# K1921VG1T register map
Vendor: NIIET; Series: K1921VGx; File version: 2.8
CPU: other r0p1, little endian, MPU, FPU, 4 interrupt priority bits
Registers are 32-bit, read-write, reset 0x0 unless marked. A register's access mark holds for its fields unless they carry their own. Offsets are from the block's base; [hi:lo] are bit positions; {n}, {i} and the like mark numbered series; 'fields as' and 'values as' point back to an identical list.

## DAC0 — DAC control registers
Base 0x51004000
Same registers: DAC1 0x51005000
0x00 DATA12 — Output data register (12-bit)
  [11:0] VAL
0x04 DATA8 — Output data register (8-bit)
  [7:0] VAL — Write 8 most significant bits (4 less significant bits will be set to 0)
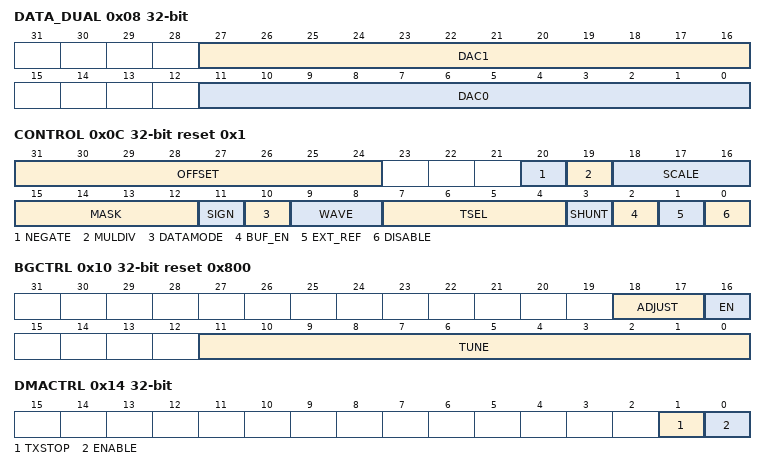
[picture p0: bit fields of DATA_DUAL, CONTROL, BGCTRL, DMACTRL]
0x08 DATA_DUAL — Output data register (Dual mode and DAC0 only)
  [27:16] DAC1 — Value for DAC1 in Dual mode
  [11:0] DAC0 — Value for DAC0 in Dual mode
0x0C CONTROL reset 0x1
  [31:24] OFFSET — Offset for pattern generator
  [20] NEGATE — Convert data to it's two's complement value
  [19] MULDIV — Switch between up and downscale
    0=DOWNSCALE (division (shift SCALE positions to the right)); 1=UPSCALE (multiplication (shift SCALE positions to the left))
  [18:16] SCALE — Scale value for up/downscale input data in steps by power of 2
    0=NOSHIFT (multiplication/division by 1); 1=SHIFT1 (multiplication/division by 2); 2=SHIFT2 (multiplication/division by 4); 3=SHIFT3 (multiplication/division by 8); 4=SHIFT4 (multiplication/division by 16); 5=SHIFT5 (multiplication/division by 32); 6=SHIFT6 (multiplication/division by 64); 7=SHIFT7 (multiplication/division by 128)
  [15:12] MASK — DAC channel mask/amplitude selector
  [11] SIGN — Signed DAC mode enable
    0=UNSIGNED (Data treated as unsigned value); 1=SIGNED (Data treated as signed values)
  [10] DATAMODE — Switch between independent and simultaneous DAC mode
    0=INDEPENDENT (Independent DAC mode); 1=SIMULTANEOUS (Simultaneous DAC mode)
  [9:8] WAVE — DAC channel wave generation enable
    0=NONE (Wave generation disabled); 1=NOISE (Noise wave generation enable); 2=TRIANGULAR (Triangular wave generation enable); 3=PATTERN (Pattern generator enable)
  [7:4] TSEL — Select DAC trigger event
    0=SWTRIG (software request by SWTRIG bit); 1=HWTRIG (hardware request from internal trigger generator); 2=TMR0123 (Timer 0 or Timer 1 or Timer 2 or Timer 3 request); 3=TMR4567 (Timer 4 or Timer 5 or Timer 6 or Timer 7 request); 4=TMR89AB (Timer 8 or Timer 9 or Timer 10 or Timer 11 request); 5=TMRCDEF (Timer 12 or Timer 13 or Timer 14 or Timer 15 request); 6=GPIOAB (GPIO A or GPIO B interrupt); 7=GPIOCD (GPIO C or GPIO D interrupt); 8=GPIOEF (GPIO E or GPIO F interrupt); 9=GPIOG (GPIO G interrupt); 10=PWMAGRP (Combined all 16 A channels of PWMs); 11=PWMBGRP (Combined all 16 B channels of PWMs)
  [3] SHUNT — Enable shunt resistor (test use only)
  [2] BUF_EN — Enable output buffer
  [1] EXT_REF — Use external reference voltage source
    0=INTERNAL_REF (Use internal reference volatage source); 1=EXTERNAL_REF (Use external 3.3 V reference volatage source)
  [0] DISABLE — Disable DAC block
0x10 BGCTRL reset 0x800 — Internal reference-voltage source (adjustable BandGap) register
  [18:17] ADJUST — Adjust output voltage of internal reference-voltage source
    0=V_1p5 (Output 1.5 V); 1=V_1p8 (Output 1.8 V); 2=V_2p048 (Output 2.048 V); 3=V_2p5 (Output 2.5 V)
  [16] EN — Turn-on internal reference-voltage source
  [11:0] TUNE — Tune bandgap voltage
0x14 DMACTRL — DAC DMA control register
  [1] TXSTOP — Automatic clear DMA TX request generation when channel ends all transactions
  [0] ENABLE — DMA request generation enable
0x18 SWTRIG wo — Software trigger control register
  [0] SWTRIG — Software trigger
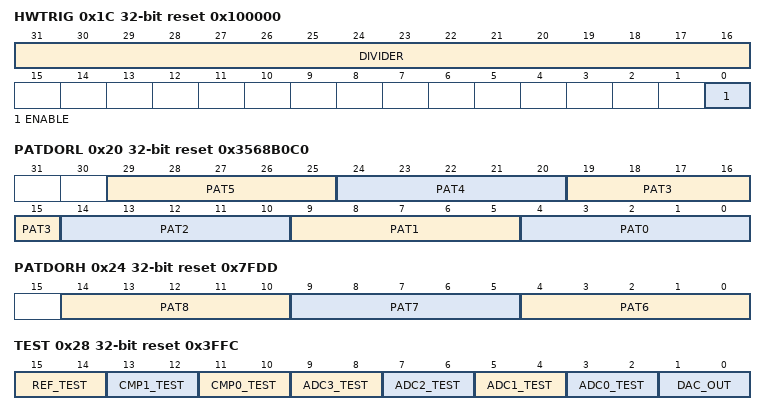
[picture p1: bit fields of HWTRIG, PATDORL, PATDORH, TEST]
0x1C HWTRIG reset 0x100000 — Internal Hardware trigger generator control register
  [31:16] DIVIDER — Frequency divider value
  [0] ENABLE — Start internal trigger generation
0x20 PATDORL reset 0x3568B0C0 — Pattern data output register (low part)
  [29:25] PAT5 — Pattern number 5 for pattern generator
    19=TRIANGLE (Triangle pattern data 5); 26=SIN (SIN pattern data 5); 31=MEANDER (Meander pattern data 5)
  [24:20] PAT4 — Pattern number 4 for pattern generator
    16=TRIANGLE (Triangle pattern data 4); 22=SIN (SIN pattern data 4); 31=MEANDER (Meander pattern data 4)
  [19:15] PAT3 — Pattern number 3 for pattern generator
    12=TRIANGLE (Triangle pattern data 3); 17=SIN (SIN pattern data 3); 31=MEANDER (Meander pattern data 3)
  [14:10] PAT2 — Pattern number 2 for pattern generator
    8=TRIANGLE (Triangle pattern data 2); 12=SIN (SIN pattern data 2); 31=MEANDER (Meander pattern data 2)
  [9:5] PAT1 — Pattern number 1 for pattern generator
    4=TRIANGLE (Triangle pattern data 1); 6=SIN (SIN pattern data 1); 31=MEANDER (Meander pattern data 1)
  [4:0] PAT0 — Pattern number 0 for pattern generator
    0=TRIANGLE_SIN (Triangle or SIN pattern data 0); 31=MEANDER (Meander pattern data 0)
0x24 PATDORH reset 0x7FDD — Pattern data output register (high part)
  [14:10] PAT8 — Pattern number 8 for pattern generator
    31=TRIANGLE_SIN_MEANDER (Triangle, SIN or meander pattern data 8)
  [9:5] PAT7 — Pattern number 7 for pattern generator
    27=TRIANGLE (Triangle pattern data 7); 30=SIN (SIN pattern data 7); 31=MEANDER (Meander pattern data 7)
  [4:0] PAT6 — Pattern number 6 for pattern generator
    23=TRIANGLE (Triangle pattern data 6); 29=SIN (SIN pattern data 6); 31=MEANDER (Meander pattern data 6)
0x28 TEST reset 0x3FFC — DAC test register
  [15:14] REF_TEST — Select output signal for reference output
    0=ZSTATE (Tri-state output); 1=DAC_REF (dac_ref for output(reserved)); 2=EXTERNAL (Connect external reference); 3=INTERNAL (Connect to internal reference)
  [13:12] CMP1_TEST — Select output signal for cmp1
    0=NORMAL (normal mode); 1=PULLUP (Connect out to AVDD); 2=PULLDOWN (Connect out to DVDD); 3=ZSTATE (Tri-state output)
  [11:10] CMP0_TEST — Select output signal for cmp0
    values as CMP1_TEST
  [2n+3:2n+2] ADC{n}_TEST (n=0..3) — Select output signal for adc{n}
    values as CMP1_TEST
  [1:0] DAC_OUT — Select output signal for dac pad
    values as CMP1_TEST
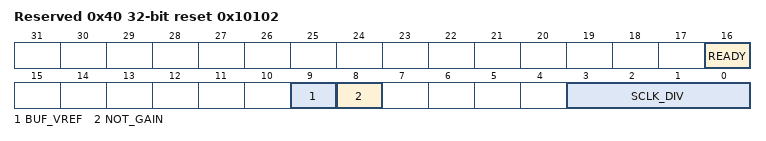
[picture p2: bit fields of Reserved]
0x40 Reserved reset 0x10102 — MCP4921 control register
  [16] READY ro — Ready to update DATA
  [9] BUF_VREF — VREF Input Buffer Control: 1 - buffered (Vref = 0.04..Vdd-0.04); 0 - unbuffered (Vref = 0..Vdd)
  [8] NOT_GAIN — Not gain output: 1 - 1x (Vout = Vref * DATA / 4096); 0 - 2x (Vout = 2 * Vref * DATA / 4096);
  [3:0] SCLK_DIV — SPI SCLK divider. SCLK period = (SCLK_DIV + 1) * 1
